# max32655 register map
Vendor: Maxim-Integrated; Series: ARMCM4; File version: 1.0
CPU: CM4 r2p1, little endian, MPU, FPU, 3 interrupt priority bits
Registers are 32-bit, read-write, reset 0x0 unless marked. A register's access mark holds for its fields unless they carry their own. Offsets are from the block's base; [hi:lo] are bit positions.

## TRIMSIR — Trim System Initilazation Registers
Base 0x40005400
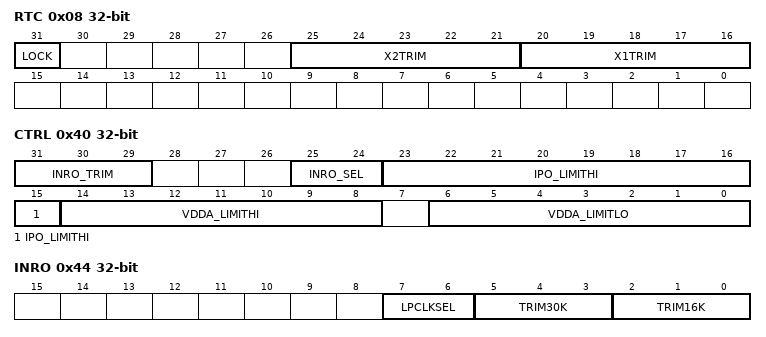
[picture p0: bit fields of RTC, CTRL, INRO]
0x08 RTC — RTC Trim System Initialization Register.
  [31] LOCK
  [25:21] X2TRIM — RTC X2 Trim.
  [20:16] X1TRIM — RTC X1 Trim.
0x34 SIMO ro — SIMO Trim System Initialization Register.
  [2:0] CLKDIV — SIMO Clock Divide.
    0=DIV1; 1=DIV16; 3=DIV32; 5=DIV64; 7=DIV128
0x3C IPOLO ro — IPO Low Trim System Initialization Register.
  [7:0] IPO_LIMITLO — IPO Low Limit Trim.
0x40 CTRL — Control Trim System Initialization Register.
  [31:29] INRO_TRIM — INRO Clock Trim.
  [25:24] INRO_SEL — INRO Clock Select.
    0=8KHZ; 1=16KHZ; 2=30KHZ
  [23:15] IPO_LIMITHI — IPO High Trim Limit.
  [14:8] VDDA_LIMITHI — VDDA High Trim Limit.
  [6:0] VDDA_LIMITLO — VDDA Low Trim Limit.
0x44 INRO — RTC Trim System Initialization Register.
  [7:6] LPCLKSEL — INRO Low Power Mode Clock Select.
    0=8KHZ; 1=16KHZ; 2=30KHZ
  [5:3] TRIM30K — INRO 30KHz Trim.
  [2:0] TRIM16K — INRO 16KHz Trim.

## TRNG — Random Number Generator.
Base 0x4004D000
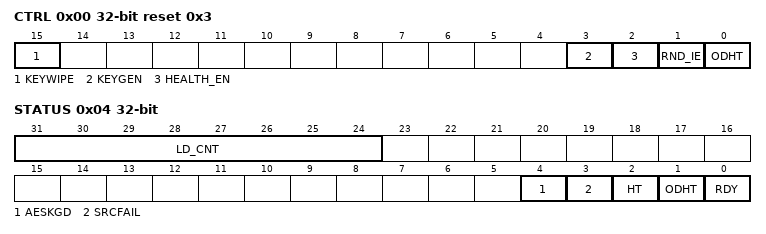
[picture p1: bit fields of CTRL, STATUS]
0x00 CTRL reset 0x3 — TRNG Control Register.
  [15] KEYWIPE — To wipe the Battery Backed key.
  [3] KEYGEN — AES Key Generate. When enabled, the key for securing NVSRAM is generated and transferred to the secure key register automatically without user visibility or intervention. This bit is cleared by hardware once the key has been transferred to the secure key register.
  [2] HEALTH_EN — Enable IRQ generation when a health test fails.
  [1] RND_IE — To enable IRQ generation when a new 32-bit Random number is ready.
    0=disable; 1=enable
  [0] ODHT — Start On-Demand health test.
0x04 STATUS — Data. The content of this register is valid only when RNG_IS = 1. When TRNG is disabled, read returns 0x0000 0000.
  [31:24] LD_CNT
  [4] AESKGD
  [3] SRCFAIL — Entropy source has failed.
  [2] HT — Health test status.
  [1] ODHT — On-Demand health test status.
  [0] RDY — 32-bit random data is ready to read from TRNG_DATA register. Reading TRNG_DATA when RND_RDY=0 will return all 0's. IRQ is generated when RND_RDY=1 if TRNG_CN.RND_IRQ_EN=1.
    0=Busy (TRNG Busy); 1=Ready (32 bit random data is ready)
0x08 DATA ro — Data. The content of this register is valid only when RNG_IS = 1. When TRNG is disabled, read returns 0x0000 0000.
  [31:0] DATA — Data. The content of this register is valid only when RNG_IS =1. When TNRG is disabled, read returns 0x0000 0000.

## WUT — 32-bit reloadable timer that can be used for timing and wakeup.
Base 0x40006400
0x00 CNT reset 0x1 — Count. This register stores the current timer count.
  [31:0] COUNT — Timer Count Value.
0x04 CMP reset 0xFFFF — Compare. This register stores the compare value, which is used to set the maximum count value to initiate a reload of the timer to 0x0001.
  [31:0] COMPARE — Timer Compare Value.
0x0C INTR write-1-clears — Clear Interrupt. Writing a value (0 or 1) to a bit in this register clears the associated interrupt.
  [0] IRQ_CLR — Clear Interrupt.
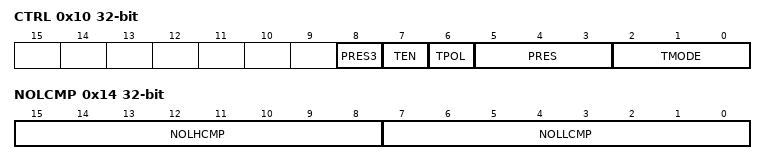
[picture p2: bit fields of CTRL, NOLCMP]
0x10 CTRL — Timer Control Register.
  [8] PRES3 — MSB of prescaler value.
  [7] TEN — Timer Enable.
    0=dis (Disable.); 1=en (Enable.)
  [6] TPOL — Timer input/output polarity bit.
    0=Active High; 1=Active Low
  [5:3] PRES — Prescaler. Set the Timer's prescaler value. The prescaler divides the PCLK input to the timer and sets the Timer's Count Clock, F_CNT_CLK = PCLK(HZ)/prescaler. The Timer's prescaler setting is a 4-bit value with pres3:pres[2:0].
    0=div1 (Divide by 1.); 1=div2 (Divide by 2.); 2=div4 (Divide by 4.); 3=div8 (Divide by 8.); 4=div16 (Divide by 16.); 5=div32 (Divide by 32.); 6=div64 (Divide by 64.); 7=div128 (Divide by 128.)
  [2:0] TMODE — Timer Mode.
    0=One Shot Mode; 1=Continuous Mode; 2=Counter Mode; 4=Capture Mode; 5=Compare Mode; 6=Gated Mode; 7=Capture/Compare Mode
0x14 NOLCMP — Timer Non-Overlapping Compare Register.
  [15:8] NOLHCMP — Non-overlapping High Compare. The 8-bit timer count value of non-overlapping time between falling edge of PWM output 0A' and next rising edge of PWM output 0A.
  [7:0] NOLLCMP — Non-overlapping Low Compare. The 8-bit timer count value of non-overlapping time between falling edge of PWM output 0A and next rising edge of PWM output 0A'.
0x18 PRESET
  [31:0] PRESET — Preset Value.
0x1C RELOAD
  [31:0] RELOAD — Rerload Value.
0x20 SNAPSHOT
  [31:0] SNAPSHOT — Snapshot Value.
